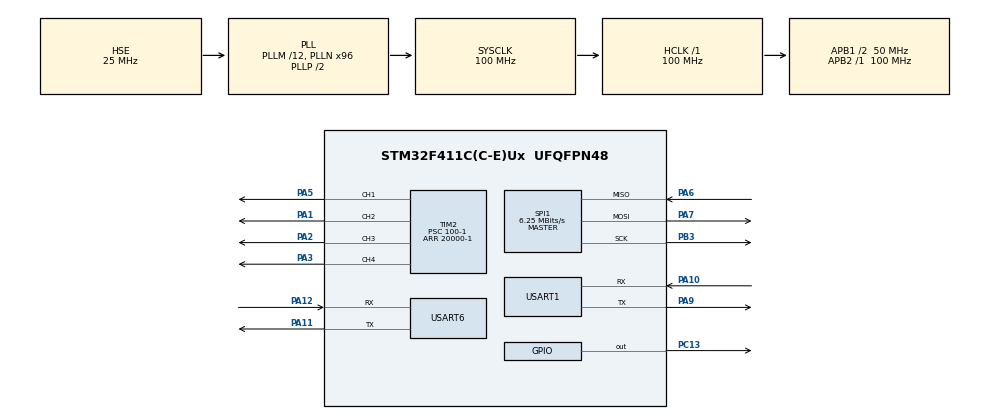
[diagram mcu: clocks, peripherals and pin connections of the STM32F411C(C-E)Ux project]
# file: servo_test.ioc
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Mcu.Family=STM32F4
Mcu.Name=STM32F411C(C-E)Ux
Mcu.Package=UFQFPN48
NVIC.PriorityGroup=NVIC_PRIORITYGROUP_4
NVIC.USART6_IRQn=true\:0\:0\:false\:false\:true\:true\:true\:true
PA1.Signal=S_TIM2_CH2
PA10.Mode=Asynchronous
PA10.Signal=USART1_RX
PA11.Mode=Asynchronous
PA11.Signal=USART6_TX
PA12.Mode=Asynchronous
PA12.Signal=USART6_RX
PA13.Mode=Serial_Wire
PA13.Signal=SYS_JTMS-SWDIO
PA14.Mode=Serial_Wire
PA14.Signal=SYS_JTCK-SWCLK
PA2.Signal=S_TIM2_CH3
PA3.Signal=S_TIM2_CH4
PA5.Signal=S_TIM2_CH1_ETR
PA6.Mode=Full_Duplex_Master
PA6.Signal=SPI1_MISO
PA7.Mode=Full_Duplex_Master
PA7.Signal=SPI1_MOSI
PA9.Mode=Asynchronous
PA9.Signal=USART1_TX
PB3.Mode=Full_Duplex_Master
PB3.Signal=SPI1_SCK
PC13-ANTI_TAMP.GPIO_PuPd=GPIO_PULLUP
PC13-ANTI_TAMP.PinState=GPIO_PIN_SET
PC13-ANTI_TAMP.Signal=GPIO_Output
PC14-OSC32_IN.Mode=LSE-External-Oscillator
PC14-OSC32_IN.Signal=RCC_OSC32_IN
PC15-OSC32_OUT.Mode=LSE-External-Oscillator
PC15-OSC32_OUT.Signal=RCC_OSC32_OUT
PH0\ -\ OSC_IN.Mode=HSE-External-Oscillator
PH0\ -\ OSC_IN.Signal=RCC_OSC_IN
PH1\ -\ OSC_OUT.Mode=HSE-External-Oscillator
PH1\ -\ OSC_OUT.Signal=RCC_OSC_OUT
ProjectManager.HeapSize=0x200
ProjectManager.StackSize=0x400
ProjectManager.TargetToolchain=MDK-ARM V5
RCC.48MHZClocksFreq_Value=50000000
RCC.AHBFreq_Value=100000000
RCC.APB1CLKDivider=RCC_HCLK_DIV2
RCC.APB1Freq_Value=50000000
RCC.APB1TimFreq_Value=100000000
RCC.APB2Freq_Value=100000000
RCC.APB2TimFreq_Value=100000000
RCC.CortexFreq_Value=100000000
RCC.HCLKFreq_Value=100000000
RCC.HSE_VALUE=25000000
RCC.HSI_VALUE=16000000
RCC.PLLM=12
RCC.PLLN=96
RCC.PLLSourceVirtual=RCC_PLLSOURCE_HSE
RCC.SYSCLKFreq_VALUE=100000000
RCC.SYSCLKSource=RCC_SYSCLKSOURCE_PLLCLK
RCC.VCOOutputFreq_Value=200000000
SH.S_TIM2_CH1_ETR.0=TIM2_CH1,PWM Generation1 CH1
SH.S_TIM2_CH2.0=TIM2_CH2,PWM Generation2 CH2
SH.S_TIM2_CH3.0=TIM2_CH3,PWM Generation3 CH3
SH.S_TIM2_CH4.0=TIM2_CH4,PWM Generation4 CH4
SPI1.BaudRatePrescaler=SPI_BAUDRATEPRESCALER_16
SPI1.CLKPhase=SPI_PHASE_2EDGE
SPI1.CalculateBaudRate=6.25 MBits/s
SPI1.DataSize=SPI_DATASIZE_16BIT
SPI1.Direction=SPI_DIRECTION_2LINES
SPI1.Mode=SPI_MODE_MASTER
SPI1.VirtualType=VM_MASTER
TIM2.AutoReloadPreload=TIM_AUTORELOAD_PRELOAD_ENABLE
TIM2.Channel-PWM\ Generation1\ CH1=TIM_CHANNEL_1
TIM2.Channel-PWM\ Generation2\ CH2=TIM_CHANNEL_2
TIM2.Channel-PWM\ Generation3\ CH3=TIM_CHANNEL_3
TIM2.Channel-PWM\ Generation4\ CH4=TIM_CHANNEL_4
TIM2.Period=20000-1
TIM2.Prescaler=100-1
USART1.VirtualMode=VM_ASYNC
USART6.VirtualMode=VM_ASYNC
VP_TIM2_VS_ClockSourceINT.Mode=Internal
board=custom

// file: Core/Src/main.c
/* USER CODE BEGIN Header */
/**
  ******************************************************************************
  * @file           : main.c
  * @brief          : Main program body
  ******************************************************************************
  * @attention
  *
  * Copyright (c) 2023 STMicroelectronics.
  * All rights reserved.
  *
  * This software is licensed under terms that can be found in the LICENSE file
  * in the root directory of this software component.
  * If no LICENSE file comes with this software, it is provided AS-IS.
  *
  ******************************************************************************
  */
/* USER CODE END Header */
#include "main.h"

void SystemClock_Config(void);

int main(void)
{

  /* MCU Configuration--------------------------------------------------------*/

  /* Reset of all peripherals, Initializes the Flash interface and the Systick. */
  HAL_Init();

  /* Configure the system clock */
  SystemClock_Config();

  /* Initialize all configured peripherals */
  MX_GPIO_Init();
  MX_TIM2_Init();
  MX_USART1_UART_Init();
  MX_SPI1_Init();
  MX_USART6_UART_Init();
  /* USER CODE BEGIN 2 */

//舵机pwm测试
//pa5
//	Servo_Init(&htim2, servo_1);

//磁编码测试
//cs pa4
//
//	AS5047_Init();
//	uint16_t angle;

//激光测距测试
  DFRobot_LIDAR07_packet lidar;

  LIDAR07_read_version(&lidar);
  LIDAR07_mode_set(1);
  LIDAR07_fre(&lidar,1,100);
  //LIDAR07_filter_switch(1);

  /* USER CODE END 2 */

  /* Infinite loop */
  while (1)
  {

    /* USER CODE BEGIN 3 */

    //监测
		HAL_GPIO_TogglePin(GPIOC, GPIO_PIN_13);
		HAL_Delay(1000);

    //激光测距
    LIDAR07_measure_switch(&lidar,1);
    printf("%f\r\n",lidar.distance_m);

		//Servo_set(&htim2,servo_1,20000);

		// angle=AS5047_read(0x3FFE);
    // printf("%f\r\n",(float)(angle));

  }
  /* USER CODE END 3 */
}

void SystemClock_Config(void)
{
  RCC_OscInitTypeDef RCC_OscInitStruct = {0};
  RCC_ClkInitTypeDef RCC_ClkInitStruct = {0};

  /** Configure the main internal regulator output voltage
  */
  __HAL_RCC_PWR_CLK_ENABLE();
  __HAL_PWR_VOLTAGESCALING_CONFIG(PWR_REGULATOR_VOLTAGE_SCALE1);

  /** Initializes the RCC Oscillators according to the specified parameters
  * in the RCC_OscInitTypeDef structure.
  */
  RCC_OscInitStruct.OscillatorType = RCC_OSCILLATORTYPE_HSE;
  RCC_OscInitStruct.HSEState = RCC_HSE_ON;
  RCC_OscInitStruct.PLL.PLLState = RCC_PLL_ON;
  RCC_OscInitStruct.PLL.PLLSource = RCC_PLLSOURCE_HSE;
  RCC_OscInitStruct.PLL.PLLM = 12;
  RCC_OscInitStruct.PLL.PLLN = 96;
  RCC_OscInitStruct.PLL.PLLP = RCC_PLLP_DIV2;
  RCC_OscInitStruct.PLL.PLLQ = 4;
  if (HAL_RCC_OscConfig(&RCC_OscInitStruct) != HAL_OK)
  {
    Error_Handler();
  }

  /** Initializes the CPU, AHB and APB buses clocks
  */
  RCC_ClkInitStruct.ClockType = RCC_CLOCKTYPE_HCLK|RCC_CLOCKTYPE_SYSCLK
                              |RCC_CLOCKTYPE_PCLK1|RCC_CLOCKTYPE_PCLK2;
  RCC_ClkInitStruct.SYSCLKSource = RCC_SYSCLKSOURCE_PLLCLK;
  RCC_ClkInitStruct.AHBCLKDivider = RCC_SYSCLK_DIV1;
  RCC_ClkInitStruct.APB1CLKDivider = RCC_HCLK_DIV2;
  RCC_ClkInitStruct.APB2CLKDivider = RCC_HCLK_DIV1;

  if (HAL_RCC_ClockConfig(&RCC_ClkInitStruct, FLASH_LATENCY_3) != HAL_OK)
  {
    Error_Handler();
  }
}

void Error_Handler(void)
{
  __disable_irq();
  while (1)
  {
  }
}
